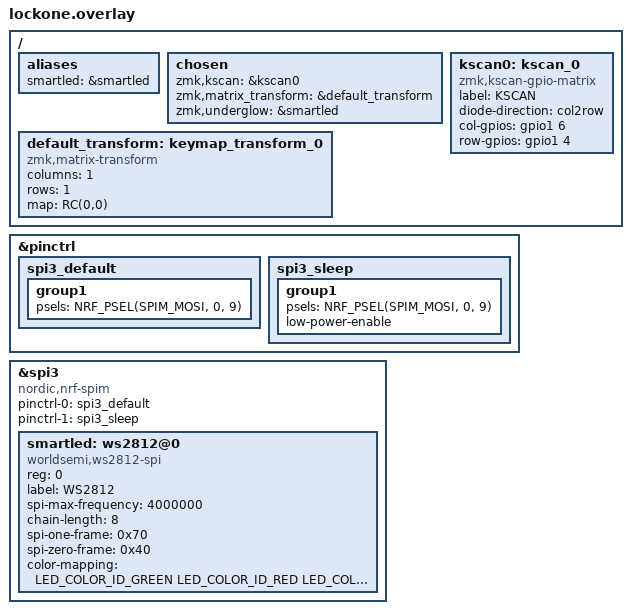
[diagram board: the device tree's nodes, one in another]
#include <dt-bindings/zmk/matrix_transform.h>
#include <dt-bindings/led/led.h>

&pinctrl {
    spi3_default: spi3_default {
        group1 {
            psels = <NRF_PSEL(SPIM_MOSI, 0, 9)>;
        };
    };
    spi3_sleep: spi3_sleep {
        group1 {
            psels = <NRF_PSEL(SPIM_MOSI, 0, 9)>;
            low-power-enable;
        };
    };
};

&spi3 {
  compatible = "nordic,nrf-spim";
  status = "okay";
  pinctrl-0 = <&spi3_default>;
  pinctrl-1 = <&spi3_sleep>;
  pinctrl-names = "default", "sleep";

  smartled: ws2812@0 {
    compatible = "worldsemi,ws2812-spi";
    reg = <0>;
	label = "WS2812";    
    spi-max-frequency = <4000000>;
    chain-length = <8>;
    spi-one-frame = <0x70>;
    spi-zero-frame = <0x40>;
    color-mapping = <LED_COLOR_ID_GREEN LED_COLOR_ID_RED LED_COLOR_ID_BLUE>;
  };
};

/ {
    aliases {
        smartled = &smartled;
    };

    chosen {
        zmk,kscan = &kscan0;
        zmk,matrix_transform = &default_transform;
		zmk,underglow = &smartled;
    };

    default_transform: keymap_transform_0 {
        compatible = "zmk,matrix-transform";
        columns = <1>;
        rows = <1>;
        map = <
        RC(0,0) >;
    };

    kscan0: kscan_0 {
        compatible = "zmk,kscan-gpio-matrix";
        label = "KSCAN";
        diode-direction = "col2row";
        col-gpios = <&gpio1 6 GPIO_ACTIVE_HIGH>
				  ;
        row-gpios = <&gpio1 4  (GPIO_ACTIVE_HIGH | GPIO_PULL_DOWN)>
				  ;
    };
};
